# f2838x_cm_mcan_regs register map
Vendor: Texas Instruments
Peripheral module from a debugger description file (folder C2000).
Address unit: 16 bits
Registers are 32-bit, read-write, no defined reset value unless marked. A register's access mark holds for its fields unless they carry their own. Offsets are as the file gives them; lines under a group give offsets from that group; [hi:lo] are bit positions; {n}, {i} and the like mark numbered series; 'fields as' and 'values as' point back to an identical list; <NAME> marks a mode.

## MCAN_REGS — MCAN Registers
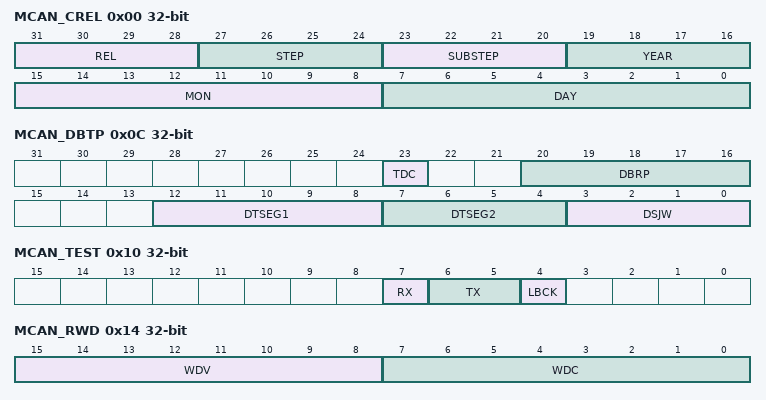
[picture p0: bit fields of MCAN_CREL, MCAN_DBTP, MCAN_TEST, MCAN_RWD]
0x00 MCAN_CREL ro — MCAN Core Release Register
  [31:28] REL — Core Release
  [27:24] STEP — Step of Core Release
  [23:20] SUBSTEP — Sub-Step of Core Release
  [19:16] YEAR — Time Stamp Year
  [15:8] MON — Time Stamp Month
  [7:0] DAY — Time Stamp Day
0x04 MCAN_ENDN ro — MCAN Endian Register
  [31:0] ETV — Endianess Test Value
0x0C MCAN_DBTP — MCAN Data Bit Timing and Prescaler Register
  [23] TDC — Transmitter Delay Compensation
  [20:16] DBRP — Data Bit Rate Prescaler
  [12:8] DTSEG1 — Data Time Segment Before Sample Point
  [7:4] DTSEG2 — Data Time Segment After Sample Point
  [3:0] DSJW — Data Resynchronization Jump Width
0x10 MCAN_TEST access per field
  [7] RX ro — Receive Pin
  [6:5] TX rw — Control of Transmit Pin
  [4] LBCK rw — Loop Back Mode
0x14 MCAN_RWD access per field — MCAN RAM Watchdog
  [15:8] WDV ro — Watchdog Value
  [7:0] WDC rw — Watchdog Configuration
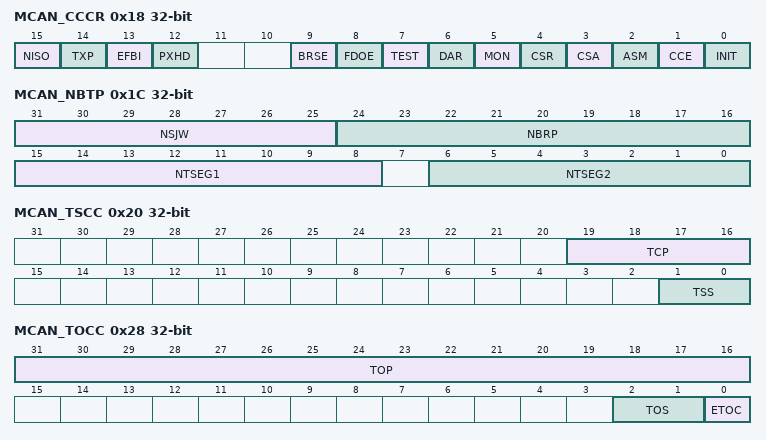
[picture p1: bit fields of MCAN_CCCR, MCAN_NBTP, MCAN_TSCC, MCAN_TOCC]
0x18 MCAN_CCCR access per field — MCAN CC Control Register
  [15] NISO rw — Non-ISO Operation
  [14] TXP rw — Transmit Pause
  [13] EFBI rw — Edge Filtering During Bus Integration
  [12] PXHD rw — Protocol Exception Handling Disable
  [9] BRSE rw — Bit Rate Switch Enable
  [8] FDOE rw — Flexible Datarate Operation Enable
  [7] TEST rw — Test Mode Enable
  [6] DAR rw — Disable Automatic Retransmission
  [5] MON rw — Bus Monitoring Mode
  [4] CSR rw — Clock Stop Request
  [3] CSA ro — Clock Stop Acknowledge
  [2] ASM rw — Restricted Operation Mode
  [1] CCE rw — Configuration Change Enable
  [0] INIT rw — Initialization
0x1C MCAN_NBTP — MCAN Nominal Bit Timing and Prescaler Register
  [31:25] NSJW — Nominal (Re)Synchronization Jump Width
  [24:16] NBRP — Nominal Bit Rate Prescaler
  [15:8] NTSEG1 — Nominal Time Segment Before Sample Point
  [6:0] NTSEG2 — Nominal Time Segment After Sample Point
0x20 MCAN_TSCC — MCAN Timestamp Counter Configuration
  [19:16] TCP — Timestamp Counter Prescaler
  [1:0] TSS — Timestamp Select
0x24 MCAN_TSCV — MCAN Timestamp Counter Value
  [15:0] TSC — Timestamp Counter
0x28 MCAN_TOCC — MCAN Timeout Counter Configuration
  [31:16] TOP — Timeout Period
  [2:1] TOS — Timeout Select
  [0] ETOC — Enable Timeout Counter
0x2C MCAN_TOCV — MCAN Timeout Counter Value
  [15:0] TOC — Timeout Counter
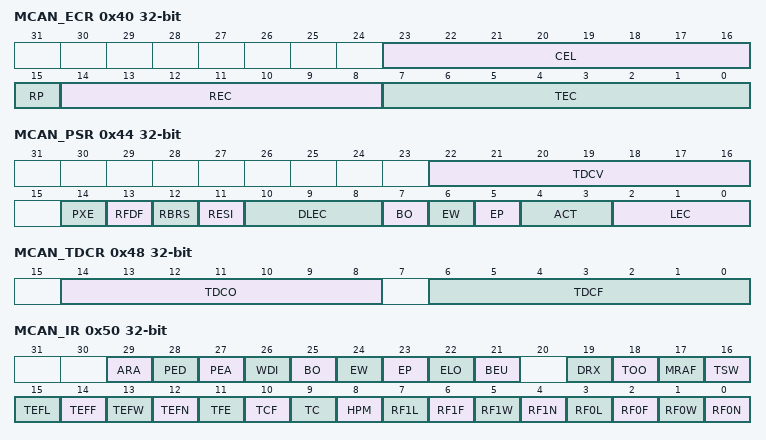
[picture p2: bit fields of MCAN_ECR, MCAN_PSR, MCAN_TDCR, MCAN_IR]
0x40 MCAN_ECR ro — MCAN Error Counter Register
  [23:16] CEL — CAN Error Logging
  [15] RP — Receive Error Passive
  [14:8] REC — Receive Error Counter
  [7:0] TEC — Transmit Error Counter
0x44 MCAN_PSR ro — MCAN Protocol Status Register
  [22:16] TDCV — Transmitter Delay Compensation Value
  [14] PXE — Protocol Exception Event
  [13] RFDF — Received a CAN FD Message
  [12] RBRS — BRS Flag of Last Received CAN FD Message
  [11] RESI — ESI Flag of Last Received CAN FD Message
  [10:8] DLEC — Data Phase Last Error Code
  [7] BO — Bus_Off Status
  [6] EW — Warning Status
  [5] EP — Error Passive
  [4:3] ACT — Node Activity
  [2:0] LEC — Last Error Code
0x48 MCAN_TDCR — MCAN Transmitter Delay Compensation Register
  [14:8] TDCO — Transmitter Delay Compensation Offset
  [6:0] TDCF — Transmitter Delay Compensation Filter Window Length
0x50 MCAN_IR — MCAN Interrupt Register
  [29] ARA — Access to Reserved Address
  [28] PED — Protocol Error in Data Phase
  [27] PEA — Protocol Error in Arbitration Phase
  [26] WDI — Watchdog Interrupt
  [25] BO — Bus_Off Status
  [24] EW — Warning Status
  [23] EP — Error Passive
  [22] ELO — Error Logging Overflow
  [21] BEU — Bit Error Uncorrected
  [19] DRX — Message Stored to Dedicated Rx Buffer
  [18] TOO — Timeout Occurred
  [17] MRAF — Message RAM Access Failure
  [16] TSW — Timestamp Wraparound
  [15] TEFL — Tx Event FIFO Element Lost
  [14] TEFF — Tx Event FIFO Full
  [13] TEFW — Tx Event FIFO Watermark Reached
  [12] TEFN — Tx Event FIFO New Entry
  [11] TFE — Tx FIFO Empty
  [10] TCF — Transmission Cancellation Finished
  [9] TC — Transmission Completed
  [8] HPM — High Priority Message
  [7] RF1L — Rx FIFO 1 Message Lost
  [6] RF1F — Rx FIFO 1 Full
  [5] RF1W — Rx FIFO 1 Watermark Reached
  [4] RF1N — Rx FIFO 1 New Message
  [3] RF0L — Rx FIFO 0 Message Lost
  [2] RF0F — Rx FIFO 0 Full
  [1] RF0W — Rx FIFO 0 Watermark Reached
  [0] RF0N — Rx FIFO 0 New Message
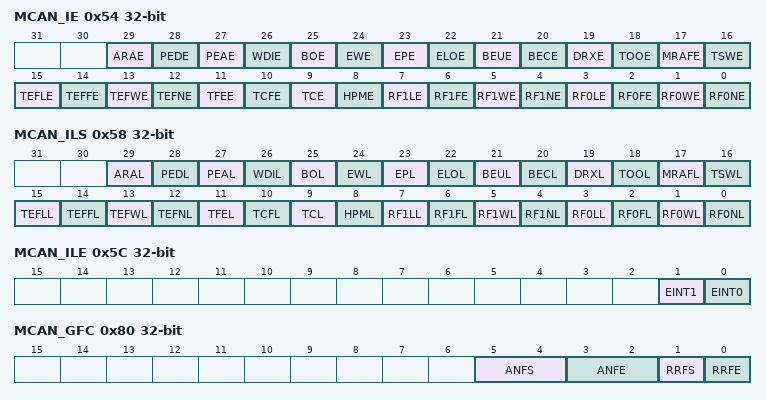
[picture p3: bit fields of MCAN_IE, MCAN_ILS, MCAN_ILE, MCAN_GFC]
0x54 MCAN_IE — MCAN Interrupt Enable
  [29] ARAE — Access to Reserved Address Enable
  [28] PEDE — Protocol Error in Data Phase Enable
  [27] PEAE — Protocol Error in Arbitration Phase Enable
  [26] WDIE — Watchdog Interrupt Enable
  [25] BOE — Bus_Off Status Enable
  [24] EWE — Warning Status Enable
  [23] EPE — Error Passive Enable
  [22] ELOE — Error Logging Overflow Enable
  [21] BEUE — Bit Error Uncorrected Enable
  [20] BECE — Bit Error Corrected Enable
  [19] DRXE — Message Stored to Dedicated Rx Buffer Enable
  [18] TOOE — Timeout Occurred Enable
  [17] MRAFE — Message RAM Access Failure Enable
  [16] TSWE — Timestamp Wraparound Enable
  [15] TEFLE — Tx Event FIFO Element Lost Enable
  [14] TEFFE — Tx Event FIFO Full Enable
  [13] TEFWE — Tx Event FIFO Watermark Reached Enable
  [12] TEFNE — Tx Event FIFO New Entry Enable
  [11] TFEE — Tx FIFO Empty Enable
  [10] TCFE — Transmission Cancellation Finished Enable
  [9] TCE — Transmission Completed Enable
  [8] HPME — High Priority Message Enable
  [7] RF1LE — Rx FIFO 1 Message Lost Enable
  [6] RF1FE — Rx FIFO 1 Full Enable
  [5] RF1WE — Rx FIFO 1 Watermark Reached Enable
  [4] RF1NE — Rx FIFO 1 New Message Enable
  [3] RF0LE — Rx FIFO 0 Message Lost Enable
  [2] RF0FE — Rx FIFO 0 Full Enable
  [1] RF0WE — Rx FIFO 0 Watermark Reached Enable
  [0] RF0NE — Rx FIFO 0 New Message Enable
0x58 MCAN_ILS — MCAN Interrupt Line Select
  [29] ARAL — Access to Reserved Address Line
  [28] PEDL — Protocol Error in Data Phase Line
  [27] PEAL — Protocol Error in Arbitration Phase Line
  [26] WDIL — Watchdog Interrupt Line
  [25] BOL — Bus_Off Status Line
  [24] EWL — Warning Status Line
  [23] EPL — Error Passive Line
  [22] ELOL — Error Logging Overflow Line
  [21] BEUL — Bit Error Uncorrected Line
  [20] BECL — Bit Error Corrected Line
  [19] DRXL — Message Stored to Dedicated Rx Buffer Line
  [18] TOOL — Timeout Occurred Line
  [17] MRAFL — Message RAM Access Failure Line
  [16] TSWL — Timestamp Wraparound Line
  [15] TEFLL — Tx Event FIFO Element Lost Line
  [14] TEFFL — Tx Event FIFO Full Line
  [13] TEFWL — Tx Event FIFO Watermark Reached Line
  [12] TEFNL — Tx Event FIFO New Entry Line
  [11] TFEL — Tx FIFO Empty Line
  [10] TCFL — Transmission Cancellation Finished Line
  [9] TCL — Transmission Completed Line
  [8] HPML — High Priority Message Line
  [7] RF1LL — Rx FIFO 1 Message Lost Line
  [6] RF1FL — Rx FIFO 1 Full Line
  [5] RF1WL — Rx FIFO 1 Watermark Reached Line
  [4] RF1NL — Rx FIFO 1 New Message Line
  [3] RF0LL — Rx FIFO 0 Message Lost Line
  [2] RF0FL — Rx FIFO 0 Full Line
  [1] RF0WL — Rx FIFO 0 Watermark Reached Line
  [0] RF0NL — Rx FIFO 0 New Message Line
0x5C MCAN_ILE — MCAN Interrupt Line Enable
  [1] EINT1 — Enable Interrupt Line 1
  [0] EINT0 — Enable Interrupt Line 0
0x80 MCAN_GFC — MCAN Global Filter Configuration
  [5:4] ANFS — Accept Non-matching Frames Standard
  [3:2] ANFE — Accept Non-matching Frames Extended
  [1] RRFS — Reject Remote Frames Standard
  [0] RRFE — Reject Remote Frames Extended
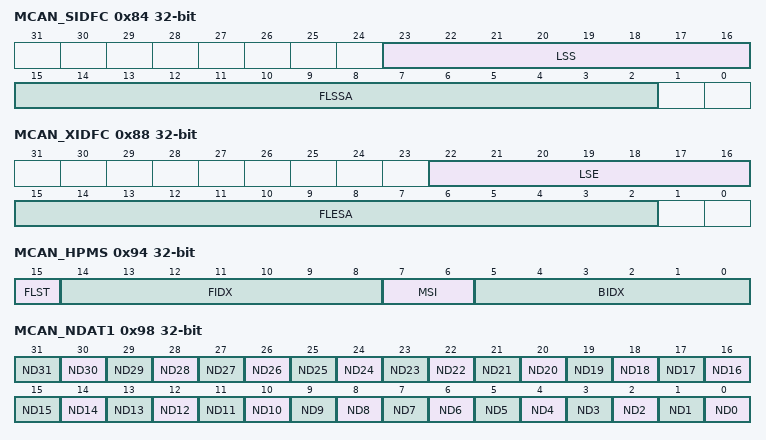
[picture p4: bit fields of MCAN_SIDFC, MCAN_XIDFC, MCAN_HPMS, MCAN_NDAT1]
0x84 MCAN_SIDFC — MCAN Standard ID Filter Configuration
  [23:16] LSS — List Size Standard
  [15:2] FLSSA — Filter List Standard Start Address
0x88 MCAN_XIDFC — MCAN Extended ID Filter Configuration
  [22:16] LSE — List Size Extended
  [15:2] FLESA — Filter List Extended Start Address
0x90 MCAN_XIDAM — MCAN Extended ID and Mask
  [28:0] EIDM — Extended ID Mask
0x94 MCAN_HPMS ro — MCAN High Priority Message Status
  [15] FLST — Filter List
  [14:8] FIDX — Filter Index
  [7:6] MSI — Message Storage Indicator
  [5:0] BIDX — Buffer Index
0x98 MCAN_NDAT1 — MCAN New Data 1
  [n] ND{n} (n=0..31) — New Data RX Buffer {n}
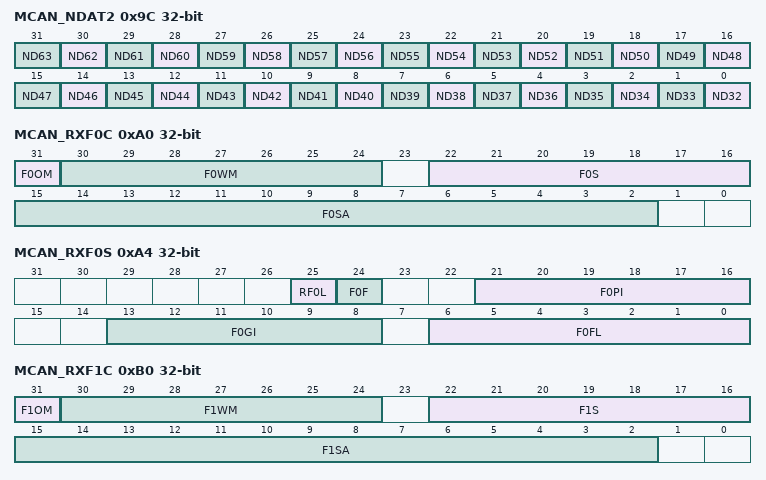
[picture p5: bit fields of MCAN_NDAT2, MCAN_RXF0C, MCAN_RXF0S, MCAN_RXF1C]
0x9C MCAN_NDAT2 — MCAN New Data 2
  [n-32] ND{n} (n=32..63) — New Data RX Buffer {n}
0xA0 MCAN_RXF0C — MCAN Rx FIFO 0 Configuration
  [31] F0OM — FIFO 0 Operation Mode
  [30:24] F0WM — Rx FIFO 0 Watermark
  [22:16] F0S — Rx FIFO 0 Size
  [15:2] F0SA — Rx FIFO 0 Start Address
0xA4 MCAN_RXF0S ro — MCAN Rx FIFO 0 Status
  [25] RF0L — Rx FIFO 0 Message Lost
  [24] F0F — Rx FIFO 0 Full
  [21:16] F0PI — Rx FIFO 0 Put Index
  [13:8] F0GI — Rx FIFO 0 Get Index
  [6:0] F0FL — Rx FIFO 0 Fill Level
0xA8 MCAN_RXF0A — MCAN Rx FIFO 0 Acknowledge
  [5:0] F0AI — Rx FIFO 0 Acknowledge Index
0xAC MCAN_RXBC — MCAN Rx Buffer Configuration
  [15:2] RBSA — Rx Buffer Start Address
0xB0 MCAN_RXF1C — MCAN Rx FIFO 1 Configuration
  [31] F1OM — FIFO 1 Operation Mode
  [30:24] F1WM — Rx FIFO 1 Watermark
  [22:16] F1S — Rx FIFO 1 Size
  [15:2] F1SA — Rx FIFO 1 Start Address
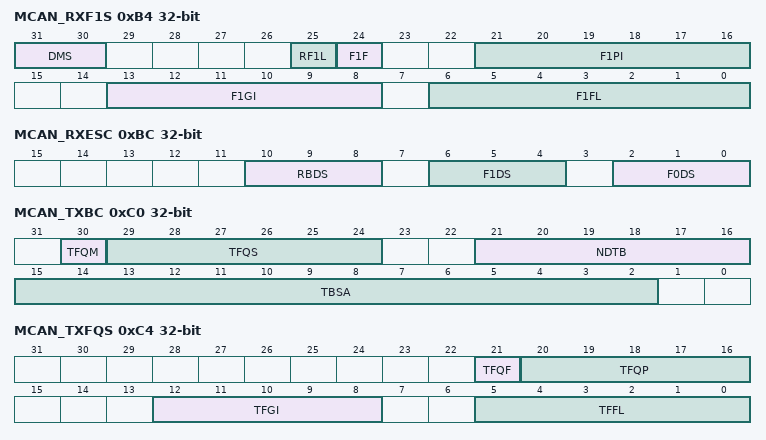
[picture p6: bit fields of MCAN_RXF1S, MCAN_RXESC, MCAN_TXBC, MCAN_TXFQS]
0xB4 MCAN_RXF1S ro — MCAN Rx FIFO 1 Status
  [31:30] DMS — Debug Message Status
  [25] RF1L — Rx FIFO 1 Message Lost
  [24] F1F — Rx FIFO 1 Full
  [21:16] F1PI — Rx FIFO 1 Put Index
  [13:8] F1GI — Rx FIFO 1 Get Index
  [6:0] F1FL — Rx FIFO 1 Fill Level
0xB8 MCAN_RXF1A — MCAN Rx FIFO 1 Acknowledge
  [5:0] F1AI — Rx FIFO 1 Acknowledge Index
0xBC MCAN_RXESC — MCAN Rx Buffer / FIFO Element Size Configuration
  [10:8] RBDS — Rx Buffer Data Field Size
  [6:4] F1DS — Rx FIFO 1 Data Field Size
  [2:0] F0DS — Rx FIFO 0 Data Field Size
0xC0 MCAN_TXBC — MCAN Tx Buffer Configuration
  [30] TFQM — Tx FIFO/Queue Mode
  [29:24] TFQS — Transmit FIFO/Queue Size
  [21:16] NDTB — Number of Dedicated Transmit Buffers
  [15:2] TBSA — Tx Buffers Start Address
0xC4 MCAN_TXFQS ro — MCAN Tx FIFO / Queue Status
  [21] TFQF — Tx FIFO/Queue Full
  [20:16] TFQP — Tx FIFO/Queue Put Index
  [12:8] TFGI — Tx FIFO Get Index
  [5:0] TFFL — Tx FIFO Free Level
0xC8 MCAN_TXESC — MCAN Tx Buffer Element Size Configuration
  [2:0] TBDS — Tx Buffer Data Field Size
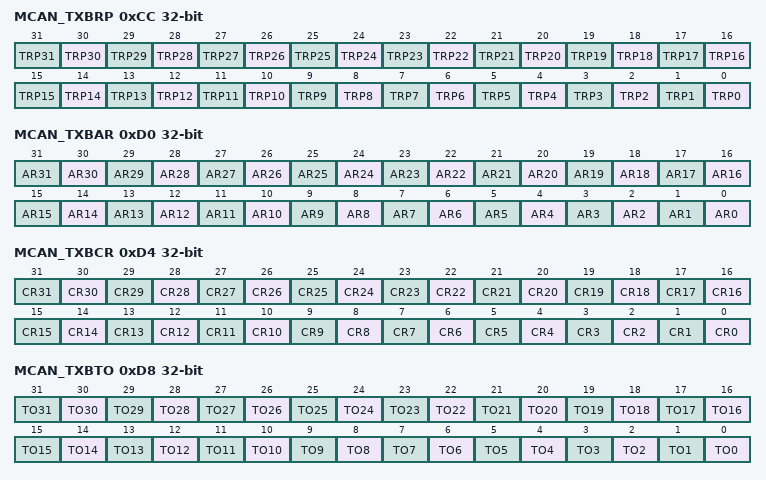
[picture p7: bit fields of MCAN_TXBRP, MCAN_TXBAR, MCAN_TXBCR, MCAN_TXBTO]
0xCC MCAN_TXBRP ro — MCAN Tx Buffer Request Pending
  [n] TRP{n} (n=0..31) — Transmission Request Pending {n}
0xD0 MCAN_TXBAR — MCAN Tx Buffer Add Request
  [n] AR{n} (n=0..31) — Add Request {n}
0xD4 MCAN_TXBCR — MCAN Tx Buffer Cancellation Request
  [n] CR{n} (n=0..31) — Cancellation Request {n}
0xD8 MCAN_TXBTO ro — MCAN Tx Buffer Transmission Occurred
  [n] TO{n} (n=0..31) — Transmission Occurred {n}
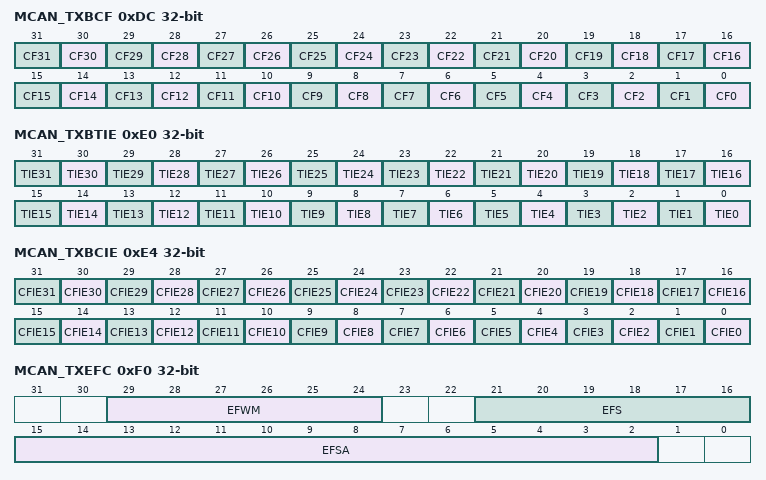
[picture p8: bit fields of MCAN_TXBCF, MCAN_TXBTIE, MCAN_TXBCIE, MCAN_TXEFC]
0xDC MCAN_TXBCF ro — MCAN Tx Buffer Cancellation Finished
  [n] CF{n} (n=0..31) — Cancellation Finished {n}
0xE0 MCAN_TXBTIE — MCAN Tx Buffer Transmission Interrupt Enable
  [n] TIE{n} (n=0..31) — Transmission Interrupt Enable {n}
0xE4 MCAN_TXBCIE — MCAN Tx Buffer Cancellation Finished Interrupt Enable
  [n] CFIE{n} (n=0..31) — Cancellation Finished Interrupt Enable {n}
0xF0 MCAN_TXEFC — MCAN Tx Event FIFO Configuration
  [29:24] EFWM — Event FIFO Watermark
  [21:16] EFS — Event FIFO Size
  [15:2] EFSA — Event FIFO Start Address
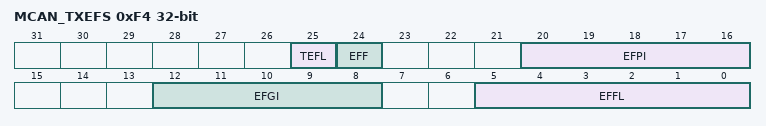
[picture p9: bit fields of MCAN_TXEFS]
0xF4 MCAN_TXEFS ro — MCAN Tx Event FIFO Status
  [25] TEFL — Tx Event FIFO Element Lost
  [24] EFF — Event FIFO Full
  [20:16] EFPI — Event FIFO Put Index
  [12:8] EFGI — Event FIFO Get Index
  [5:0] EFFL — Event FIFO Fill Level
0xF8 MCAN_TXEFA — MCAN Tx Event FIFO Acknowledge
  [4:0] EFAI — Event FIFO Acknowledge Index
